CM_ "IMPORT _subaru_preglobal_2015.dbc";

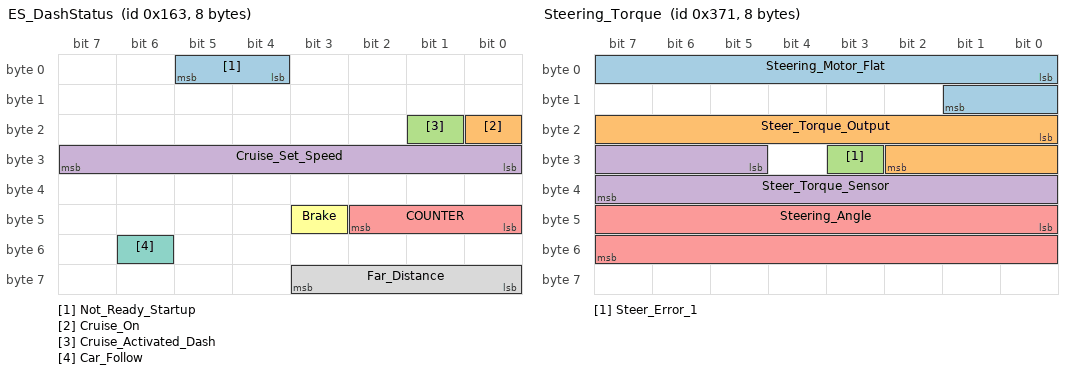
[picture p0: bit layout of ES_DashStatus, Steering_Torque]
BO_ 355 ES_DashStatus: 8 XXX
 SG_ Not_Ready_Startup : 4|2@1+ (1,0) [0|3] "" XXX
 SG_ Cruise_On : 16|1@1+ (1,0) [0|1] "" XXX
 SG_ Cruise_Activated_Dash : 17|1@0+ (1,0) [0|1] "" XXX
 SG_ Cruise_Set_Speed : 24|8@1+ (1,0) [0|255] "" XXX
 SG_ COUNTER : 40|3@1+ (1,0) [0|7] "" XXX
 SG_ Brake : 43|1@1+ (1,0) [0|1] "" XXX
 SG_ Car_Follow : 54|1@1+ (1,0) [0|1] "" XXX
 SG_ Far_Distance : 56|4@1+ (5,0) [0|75] "m" XXX

BO_ 881 Steering_Torque: 8 XXX
 SG_ Steering_Motor_Flat : 0|10@1+ (32,0) [0|1000] "" XXX
 SG_ Steer_Torque_Output : 16|11@1- (-32,0) [-1000|1000] "" XXX
 SG_ Steer_Error_1 : 27|1@1+ (1,0) [0|1] "" XXX
 SG_ Steer_Torque_Sensor : 29|11@1- (-1,0) [-1000|1000] "" XXX
 SG_ Steering_Angle : 40|16@1- (-0.033,0) [-600|600] "" XXX
